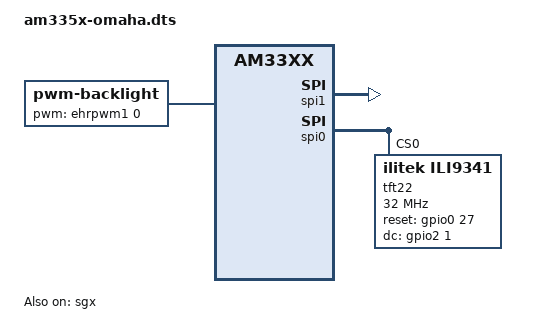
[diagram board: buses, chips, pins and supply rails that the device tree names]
/dts-v1/;

#include "am33xx.dtsi"
#include "am335x-common.dtsi"

&sgx {
	status = "okay";
};

&spi1 {
	#address-cells = <1>;
	#size-cells = <0>;
	status = "okay";

	channel@0 {
		#address-cells = <1>;
		#size-cells = <0>;
		compatible = "spidev";
		reg = <0>;
		spi-max-frequency = <24000000>;
	};

	channel@1 {
		#address-cells = <1>;
		#size-cells = <0>;
		compatible = "spidev";
		reg = <1>;
		spi-max-frequency = <24000000>;
	};
};

&spi0 {
	#address-cells = <1>;
	#size-cells = <0>;
	status = "okay";

	channel@0 {
		status = "disabled";
	};

	channel@1 {
		status = "disabled";
	};

	tft22: tft22@0 {
		compatible = "ilitek,ili9341";
		pnctrl-names = "default";
		pinctrl-0 = <
			&P1_06_spi_cs_pin
			&P1_08_spi_sclk_pin
			&P1_10_spi_pin
			&P1_12_spi_pin
			&P2_19_gpio_pin
			&P2_17_gpio_pin
		>;
		reg = <0>;
		buswidth = <8>;

		reset-gpios = <&gpio0 27 0>;
		dc-gpios = <&gpio2 1 0>;
		debug = <1>;
		spi-max-frequency = <32000000>;
		speed = <20000000>;
		rotate = <90>;
		bgr;
		fps = <25>;
	};
};

&am33xx_pinmux {
	pwm_bl_pins: pinmux_pwm_bl_pins {
		pinctrl-single,pins = <0x48 0x06>;
	};
};

&ocp {
	backlight {
		compatible = "pwm-backlight";
		pinctrl-names = "default";
		pinctrl-0 = <&pwm_bl_pins>;
		status = "okay";

		pwms = <&ehrpwm1 0 500000 0>;
		pwm-names = "backlight";
		brightness-levels=<0 4 8 16 32 64 128 255>;
		default-brightness-level = <2>;
	};
};
